# STM32G553 register map
File version: 2.0.0
CPU: CM33 r0p4, little endian, MPU, FPU, 4 interrupt priority bits
Registers are 32-bit, read-write, reset 0x0 unless marked. A register's access mark holds for its fields unless they carry their own. Offsets are from the block's base; [hi:lo] are bit positions; {n}, {i} and the like mark numbered series.

## ADCC12 — ADCC address block description
Base 0x42020300
Same registers: ADCC3 0x42020700, ADCC12_S 0x52020300, ADCC3_S 0x52020700
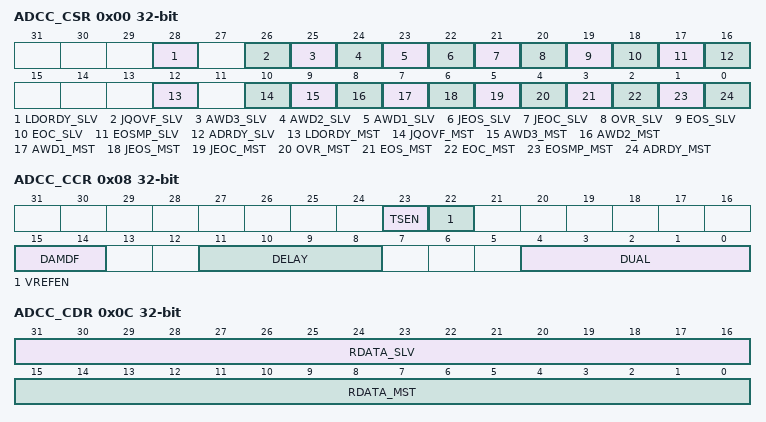
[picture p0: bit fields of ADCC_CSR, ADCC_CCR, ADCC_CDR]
0x00 ADCC_CSR ro — ADC common status register
  [28] LDORDY_SLV — ADC internal voltage regulator flag of the slave ADC
  [26] JQOVF_SLV — Injected context queue overflow flag of the slave ADC
  [25] AWD3_SLV — Analog watchdog 3 flag of the slave ADC
  [24] AWD2_SLV — Analog watchdog 2 flag of the slave ADC
  [23] AWD1_SLV — Analog watchdog 1 flag of the slave ADC
  [22] JEOS_SLV — End of injected sequence flag of the slave ADC
  [21] JEOC_SLV — End of injected conversion flag of the slave ADC
  [20] OVR_SLV — Overrun flag of the slave ADC
  [19] EOS_SLV — End of regular sequence flag of the slave ADC. This bit is a copy of the EOS bit in the corresponding ADC_ISR register.
  [18] EOC_SLV — End of regular conversion of the slave ADC
  [17] EOSMP_SLV — End of sampling phase flag of the slave ADC
  [16] ADRDY_SLV — Slave ADC ready
  [12] LDORDY_MST — ADC internal voltage regulator flag of the master ADC
  [10] JQOVF_MST — Injected context queue overflow flag of the master ADC
  [9] AWD3_MST — Analog watchdog 3 flag of the master ADC
  [8] AWD2_MST — Analog watchdog 2 flag of the master ADC
  [7] AWD1_MST — Analog watchdog 1 flag of the master ADC
  [6] JEOS_MST — End of injected sequence flag of the master ADC
  [5] JEOC_MST — End of injected conversion flag of the master ADC
  [4] OVR_MST — Overrun flag of the master ADC
  [3] EOS_MST — End of regular sequence flag of the master ADC
  [2] EOC_MST — End of regular conversion of the master ADC
  [1] EOSMP_MST — End of Sampling phase flag of the master ADC
  [0] ADRDY_MST — Master ADC ready
0x08 ADCC_CCR — ADC common control register
  [23] TSEN — Temperature sensor voltage enable
    0=Temperature sensor channel disabled; 1=Temperature sensor channel enabled
  [22] VREFEN — VREFINT enable
    0=VREFINT channel disabled; 1=VREFINT channel enabled
  [15:14] DAMDF — Dual ADC mode data format
    0=Dual ADC mode without data packing (ADCC_CDR and ADCC_CDR2 registers not used); 2=Data formatting mode for any data width (ADCC_CDR data register is used when the data width is less than 16 bits, otherwise ADCC_CDR2 register is used); 3=Data formatting mode for data width lower that 8 bits (ADCC_CDR data register is used)
  [11:8] DELAY — Delay between two sampling phases
  [4:0] DUAL — Dual ADC mode selection
    0=Independent mode; 1=Combined regular simultaneous + Injected simultaneous mode; 2=Combined regular simultaneous + Alternate trigger mode; 3=Combined interleaved mode + Injected simultaneous mode; 5=Injected simultaneous mode only; 6=Regular simultaneous mode only; 7=Interleaved mode only; 9=Alternate trigger mode only
0x0C ADCC_CDR ro — ADC common regular data register for dual mode
  [31:16] RDATA_SLV — Regular data of the slave ADC
  [15:0] RDATA_MST — Regular data of the master ADC.
0x10 ADCC_CDR2 ro — ADC common regular data register for dual mode
  [31:0] RDATA_ALT — Regular data of the master/slave alternated ADCs.

## COMP1 — COMP address block description
Base 0x44008400
Same registers: COMP2 0x44008800, COMP3 0x44008C00, COMP4 0x44009000, COMP5 0x44009400, COMP6 0x44009800, COMP7 0x44009C00, COMP8 0x4400A000, COMP{n}_S {0x54008000+0x400*n} (n=1..8)
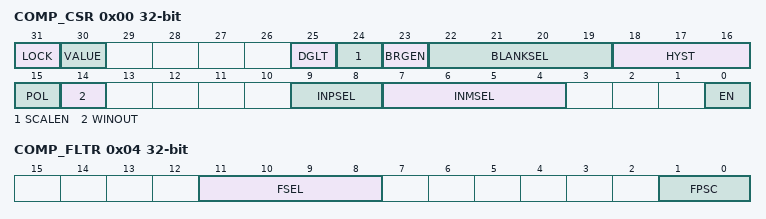
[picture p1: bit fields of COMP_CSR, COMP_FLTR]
0x00 COMP_CSR — Comparator configuration register
  [31] LOCK
    0=COMP_CxCR[31:0] and COMPx_FLTR[31:0] registers are read/write; 1=COMP_CxCR1[31:0] and COMPx_FLTR[31:0] are locked
  [30] VALUE ro — COMPx output value
  [25] DGLT — DEGLITCHER enable
    0=Disable; 1=Enable
  [24] SCALEN — VREFINT scaler enable
    0=Disable; 1=Enable
  [23] BRGEN — VREFINT scaler resistor bridge enable
    0=Disable; 1=Enable
  [22:19] BLANKSEL — Comparator x blanking signal select
  [18:16] HYST — Comparator x hysteresis
    0=No hysteresis; 1=10 mV hysteresis; 2=20 mv hysteresis; 3=30 mV hysteresis; 4=40 mV hysteresis; 5=50 mV hysteresis; 6=60 mV hysteresis; 7=70 mV hysteresis
  [15] POL — Comparator x polarity
    0=Non-inverted; 1=Inverted
  [14] WINOUT — COMPx output selector
    0=compless thansub>xless than/sub>_out = compless thansub>xless than/sub>_value; 1=compless thansub>xless than/sub>_out = WINOUT(compless thansub>xless than/sub>)
  [9:8] INPSEL — COMPx channel non-inverting input selection
  [7:4] INMSEL — COMPx channel inverting input selection
  [0] EN — COMPx channel enable
    0=Disable; 1=Enable
0x04 COMP_FLTR — Comparator filter configuration register
  [11:8] FSEL — COMPx digital filter configuration selection
    0=Filter disabled; 1=filter_sampling = comp_pclk, N = 2; 2=filter_sampling = comp_pclk, N = 4; 3=filter_sampling = comp_pclk, N = 8; 4=filter_sampling = filter_clk/2, N = 6; 5=filter_sampling = filter_clk/2, N = 8; 6=filter_sampling = filter_clk/4, N = 6; 7=filter_sampling = filter_clk/4, N = 8; 8=filter_sampling = filter_clk/8, N = 6; 9=filter_sampling = filter_clk/8, N = 8; 10=filter_sampling = filter_clk/16, N = 5; 11=filter_sampling = filter_clk/16, N = 6; 12=filter_sampling = filter_clk/16, N = 8; 13=filter_sampling = filter_clk/32, N = 5; 14=filter_sampling = filter_clk/32, N = 6; 15=filter_sampling = filter_clk/32, N = 8
  [1:0] FPSC — COMPx digital filter configuration selection
    0=filter_clk = comp_pclk; 1=filter_clk = comp_pclk/2; 2=filter_clk = comp_pclk/4; 3=filter_clk = comp_pclk/8

## Notices in the file
Copyright (c) 2026 STMicroelectronics.
SPDX-License-Identifier: Apache-2.0
Licensed under the Apache License, Version 2.0 (the "License");
you may not use this file except in compliance with the License.
You may obtain a copy of the License at
http://www.apache.org/licenses/LICENSE-2.0
Unless required by applicable law or agreed to in writing, software
distributed under the License is distributed on an "AS IS" BASIS,
WITHOUT WARRANTIES OR CONDITIONS OF ANY KIND, either express or implied.
See the License for the specific language governing permissions and
limitations under the License.
